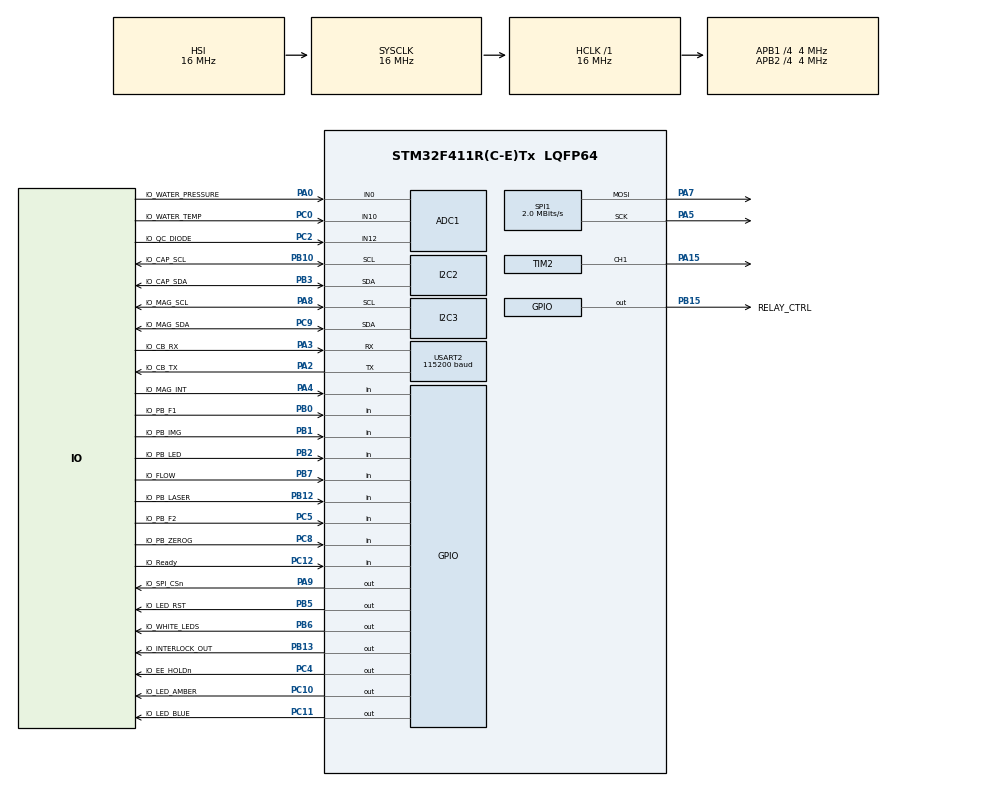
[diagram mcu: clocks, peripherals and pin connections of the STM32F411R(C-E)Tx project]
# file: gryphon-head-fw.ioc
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ADC1.Channel-0\#ChannelRegularConversion=ADC_CHANNEL_10
ADC1.ClockPrescaler=ADC_CLOCK_SYNC_PCLK_DIV6
ADC1.DMAContinuousRequests=ENABLE
ADC1.NbrOfConversionFlag=1
ADC1.Rank-0\#ChannelRegularConversion=1
ADC1.SamplingTime-0\#ChannelRegularConversion=ADC_SAMPLETIME_3CYCLES
ADC1.master=1
Dma.ADC1.0.Direction=DMA_PERIPH_TO_MEMORY
Dma.ADC1.0.FIFOMode=DMA_FIFOMODE_DISABLE
Dma.ADC1.0.Instance=DMA2_Stream0
Dma.ADC1.0.MemDataAlignment=DMA_MDATAALIGN_HALFWORD
Dma.ADC1.0.MemInc=DMA_MINC_ENABLE
Dma.ADC1.0.Mode=DMA_NORMAL
Dma.ADC1.0.PeriphDataAlignment=DMA_PDATAALIGN_HALFWORD
Dma.ADC1.0.PeriphInc=DMA_PINC_DISABLE
Dma.ADC1.0.Priority=DMA_PRIORITY_LOW
Dma.Request0=ADC1
IWDG.Prescaler=IWDG_PRESCALER_32
IWDG.Reload=1499
Mcu.Family=STM32F4
Mcu.Name=STM32F411R(C-E)Tx
Mcu.Package=LQFP64
NVIC.ADC_IRQn=true\:0\:0\:false\:false\:true\:true\:true\:true
NVIC.DMA2_Stream0_IRQn=true\:0\:0\:false\:false\:true\:false\:true\:true
NVIC.I2C2_ER_IRQn=true\:0\:0\:false\:false\:true\:true\:true\:true
NVIC.I2C2_EV_IRQn=true\:0\:0\:false\:false\:true\:true\:true\:true
NVIC.I2C3_EV_IRQn=true\:0\:0\:false\:false\:true\:true\:true\:true
NVIC.PriorityGroup=NVIC_PRIORITYGROUP_4
NVIC.TIM1_UP_TIM10_IRQn=true\:0\:0\:false\:false\:true\:true\:true\:true
NVIC.USART2_IRQn=true\:0\:0\:false\:false\:true\:true\:true\:true
PA0-WKUP.GPIO_Label=IO_WATER_PRESSURE
PA0-WKUP.Signal=ADCx_IN0
PA13.Signal=SYS_JTMS-SWDIO
PA14.Signal=SYS_JTCK-SWCLK
PA15.Signal=S_TIM2_CH1_ETR
PA2.GPIO_Label=IO_CB_TX
PA2.Mode=Asynchronous
PA2.Signal=USART2_TX
PA3.GPIO_Label=IO_CB_RX
PA3.Mode=Asynchronous
PA3.Signal=USART2_RX
PA4.GPIO_Label=IO_MAG_INT
PA4.Signal=GPIO_Input
PA5.Mode=TX_Only_Simplex_Unidirect_Master
PA5.Signal=SPI1_SCK
PA7.Mode=TX_Only_Simplex_Unidirect_Master
PA7.Signal=SPI1_MOSI
PA8.GPIO_Label=IO_MAG_SCL
PA8.GPIO_Pu=GPIO_PULLUP
PA8.Mode=I2C
PA8.Signal=I2C3_SCL
PA9.GPIO_Label=IO_SPI_CSn
PA9.GPIO_Speed=GPIO_SPEED_FREQ_VERY_HIGH
PA9.PinState=GPIO_PIN_SET
PA9.Signal=GPIO_Output
PB0.GPIO_Label=IO_PB_F1
PB0.GPIO_PuPd=GPIO_PULLUP
PB0.Signal=GPIO_Input
PB1.GPIO_Label=IO_PB_IMG
PB1.GPIO_PuPd=GPIO_PULLUP
PB1.Signal=GPIO_Input
PB10.GPIO_Label=IO_CAP_SCL
PB10.GPIO_Pu=GPIO_PULLUP
PB10.Mode=I2C
PB10.Signal=I2C2_SCL
PB12.GPIO_Label=IO_PB_LASER
PB12.GPIO_PuPd=GPIO_PULLUP
PB12.Signal=GPIO_Input
PB13.GPIO_Label=IO_INTERLOCK_OUT
PB13.Signal=GPIO_Output
PB15.GPIO_Label=RELAY_CTRL
PB15.Signal=GPIO_Output
PB2.GPIO_Label=IO_PB_LED
PB2.GPIO_PuPd=GPIO_PULLUP
PB2.Signal=GPIO_Input
PB3.GPIO_Label=IO_CAP_SDA
PB3.GPIO_Pu=GPIO_PULLUP
PB3.Mode=I2C
PB3.Signal=I2C2_SDA
PB5.GPIO_Label=IO_LED_RST
PB5.PinState=GPIO_PIN_SET
PB5.Signal=GPIO_Output
PB6.GPIO_Label=IO_WHITE_LEDS
PB6.GPIO_Speed=GPIO_SPEED_FREQ_LOW
PB6.Signal=GPIO_Output
PB7.GPIO_Label=IO_FLOW
PB7.Signal=GPIO_Input
PB8.GPIO_Label=IO_LED_SCL
PB8.GPIO_Pu=GPIO_PULLUP
PB8.Signal=I2C1_SCL
PB9.GPIO_Label=IO_LED_SDA
PB9.GPIO_Pu=GPIO_PULLUP
PB9.Signal=I2C1_SDA
PC0.GPIO_Label=IO_WATER_TEMP
PC0.Signal=ADCx_IN10
PC10.GPIO_Label=IO_LED_AMBER
PC10.Signal=GPIO_Output
PC11.GPIO_Label=IO_LED_BLUE
PC11.Signal=GPIO_Output
PC12.GPIO_Label=IO_Ready
PC12.Signal=GPIO_Input
PC2.GPIO_Label=IO_QC_DIODE
PC2.Signal=ADCx_IN12
PC4.GPIO_Label=IO_EE_HOLDn
PC4.PinState=GPIO_PIN_SET
PC4.Signal=GPIO_Output
PC5.GPIO_Label=IO_PB_F2
PC5.GPIO_PuPd=GPIO_PULLUP
PC5.Signal=GPIO_Input
PC8.GPIO_Label=IO_PB_ZEROG
PC8.Signal=GPIO_Input
PC9.GPIO_Label=IO_MAG_SDA
PC9.GPIO_Pu=GPIO_PULLUP
PC9.Mode=I2C
PC9.Signal=I2C3_SDA
PH0\ -\ OSC_IN.Mode=HSE-External-Oscillator
PH0\ -\ OSC_IN.Signal=RCC_OSC_IN
PH1\ -\ OSC_OUT.Mode=HSE-External-Oscillator
PH1\ -\ OSC_OUT.Signal=RCC_OSC_OUT
ProjectManager.HeapSize=0x200
ProjectManager.StackSize=0x400
ProjectManager.TargetToolchain=STM32CubeIDE
RCC.48MHZClocksFreq_Value=32000000
RCC.AHBFreq_Value=16000000
RCC.APB1CLKDivider=RCC_HCLK_DIV4
RCC.APB1Freq_Value=4000000
RCC.APB1TimFreq_Value=8000000
RCC.APB2CLKDivider=RCC_HCLK_DIV4
RCC.APB2Freq_Value=4000000
RCC.APB2TimFreq_Value=8000000
RCC.CortexFreq_Value=16000000
RCC.HCLKFreq_Value=16000000
RCC.HSE_VALUE=25000000
RCC.HSI_VALUE=16000000
RCC.LSE_VALUE=32768
RCC.PLLM=8
RCC.PLLN=64
RCC.SYSCLKFreq_VALUE=16000000
RCC.VCOOutputFreq_Value=128000000
SH.ADCx_IN0.0=ADC1_IN0,IN0
SH.ADCx_IN10.0=ADC1_IN10,IN10
SH.ADCx_IN12.0=ADC1_IN12,IN12
SH.S_TIM2_CH1_ETR.0=TIM2_CH1,PWM Generation1 CH1
SPI1.CLKPhase=SPI_PHASE_2EDGE
SPI1.CLKPolarity=SPI_POLARITY_HIGH
SPI1.CalculateBaudRate=2.0 MBits/s
SPI1.Direction=SPI_DIRECTION_2LINES
SPI1.Mode=SPI_MODE_MASTER
SPI1.VirtualType=VM_MASTER
TIM10.Channel=TIM_CHANNEL_1
TIM10.Prescaler=3200
TIM10.Pulse=10
TIM2.Channel-PWM\ Generation1\ CH1=TIM_CHANNEL_1
TIM2.Period=1000-1
TIM2.Prescaler=72-1
TIM2.TIM_MasterOutputTrigger=TIM_TRGO_UPDATE
USART2.BaudRate=115200
USART2.VirtualMode=VM_ASYNC
VP_IWDG_VS_IWDG.Mode=IWDG_Activate
VP_TIM10_VS_ClockSourceINT.Mode=Enable_Timer
VP_TIM10_VS_no_output1.Mode=Output Compare1 No Output
VP_TIM2_VS_ClockSourceINT.Mode=Internal
board=custom

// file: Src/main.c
/* USER CODE BEGIN Header */
/**
  ******************************************************************************
  * @file           : main.c
  * @brief          : Main program body
  ******************************************************************************
  * @attention
  *
  * <h2><center>&copy; Copyright (c) 2019 STMicroelectronics.
  * All rights reserved.</center></h2>
  *
  * This software component is licensed by ST under BSD 3-Clause license,
  * the "License"; You may not use this file except in compliance with the
  * License. You may obtain a copy of the License at:
  *                        opensource.org/licenses/BSD-3-Clause
  *
  ******************************************************************************
  */
/* USER CODE END Header */
#include "main.h"

/* USER CODE BEGIN Includes */
#include "../SensusSrc/setup.h"
/* USER CODE END Includes */

ADC_HandleTypeDef hadc1;
DMA_HandleTypeDef hdma_adc1;

I2C_HandleTypeDef hi2c2;
I2C_HandleTypeDef hi2c3;

IWDG_HandleTypeDef hiwdg;

SPI_HandleTypeDef hspi1;

TIM_HandleTypeDef htim2;
TIM_HandleTypeDef htim10;

UART_HandleTypeDef huart2;

void SystemClock_Config(void);
static void MX_GPIO_Init(void);
static void MX_DMA_Init(void);
static void MX_ADC1_Init(void);
static void MX_I2C2_Init(void);
static void MX_I2C3_Init(void);
static void MX_USART2_UART_Init(void);
static void MX_TIM10_Init(void);
static void MX_IWDG_Init(void);
static void MX_SPI1_Init(void);
static void MX_TIM2_Init(void);

int main(void)
{

  /* MCU Configuration--------------------------------------------------------*/

  /* Reset of all peripherals, Initializes the Flash interface and the Systick. */
  HAL_Init();

  /* Configure the system clock */
  SystemClock_Config();

  /* Initialize all configured peripherals */
  MX_GPIO_Init();
  MX_DMA_Init();
  MX_ADC1_Init();
  MX_I2C2_Init();
  MX_I2C3_Init();
  MX_USART2_UART_Init();
  MX_TIM10_Init();
  MX_IWDG_Init();
  MX_SPI1_Init();
  MX_TIM2_Init();
  /* USER CODE BEGIN 2 */
  run_setup();
  /* USER CODE END 2 */

  /* Infinite loop */
  /* USER CODE BEGIN WHILE */
  while (1)
  {
	  run_loop();

	  // Pet the dog. 1.5ms wdg timeout.
	  HAL_IWDG_Refresh(&hiwdg);
    /* USER CODE END WHILE */

  }
}

void SystemClock_Config(void)
{
  RCC_OscInitTypeDef RCC_OscInitStruct = {0};
  RCC_ClkInitTypeDef RCC_ClkInitStruct = {0};

  /** Configure the main internal regulator output voltage
  */
  __HAL_RCC_PWR_CLK_ENABLE();
  __HAL_PWR_VOLTAGESCALING_CONFIG(PWR_REGULATOR_VOLTAGE_SCALE1);

  /** Initializes the RCC Oscillators according to the specified parameters
  * in the RCC_OscInitTypeDef structure.
  */
  RCC_OscInitStruct.OscillatorType = RCC_OSCILLATORTYPE_HSI|RCC_OSCILLATORTYPE_LSI;
  RCC_OscInitStruct.HSIState = RCC_HSI_ON;
  RCC_OscInitStruct.HSICalibrationValue = RCC_HSICALIBRATION_DEFAULT;
  RCC_OscInitStruct.LSIState = RCC_LSI_ON;
  RCC_OscInitStruct.PLL.PLLState = RCC_PLL_NONE;
  if (HAL_RCC_OscConfig(&RCC_OscInitStruct) != HAL_OK)
  {
    Error_Handler();
  }

  /** Initializes the CPU, AHB and APB buses clocks
  */
  RCC_ClkInitStruct.ClockType = RCC_CLOCKTYPE_HCLK|RCC_CLOCKTYPE_SYSCLK
                              |RCC_CLOCKTYPE_PCLK1|RCC_CLOCKTYPE_PCLK2;
  RCC_ClkInitStruct.SYSCLKSource = RCC_SYSCLKSOURCE_HSI;
  RCC_ClkInitStruct.AHBCLKDivider = RCC_SYSCLK_DIV1;
  RCC_ClkInitStruct.APB1CLKDivider = RCC_HCLK_DIV4;
  RCC_ClkInitStruct.APB2CLKDivider = RCC_HCLK_DIV4;

  if (HAL_RCC_ClockConfig(&RCC_ClkInitStruct, FLASH_LATENCY_0) != HAL_OK)
  {
    Error_Handler();
  }
}

static void MX_ADC1_Init(void)
{

  ADC_ChannelConfTypeDef sConfig = {0};

  /** Configure the global features of the ADC (Clock, Resolution, Data Alignment and number of conversion)
  */
  hadc1.Instance = ADC1;
  hadc1.Init.ClockPrescaler = ADC_CLOCK_SYNC_PCLK_DIV6;
  hadc1.Init.Resolution = ADC_RESOLUTION_12B;
  hadc1.Init.ScanConvMode = DISABLE;
  hadc1.Init.ContinuousConvMode = DISABLE;
  hadc1.Init.DiscontinuousConvMode = DISABLE;
  hadc1.Init.ExternalTrigConvEdge = ADC_EXTERNALTRIGCONVEDGE_NONE;
  hadc1.Init.ExternalTrigConv = ADC_SOFTWARE_START;
  hadc1.Init.DataAlign = ADC_DATAALIGN_RIGHT;
  hadc1.Init.NbrOfConversion = 1;
  hadc1.Init.DMAContinuousRequests = ENABLE;
  hadc1.Init.EOCSelection = ADC_EOC_SINGLE_CONV;
  if (HAL_ADC_Init(&hadc1) != HAL_OK)
  {
    Error_Handler();
  }

  /** Configure for the selected ADC regular channel its corresponding rank in the sequencer and its sample time.
  */
  sConfig.Channel = ADC_CHANNEL_10;
  sConfig.Rank = 1;
  sConfig.SamplingTime = ADC_SAMPLETIME_3CYCLES;
  if (HAL_ADC_ConfigChannel(&hadc1, &sConfig) != HAL_OK)
  {
    Error_Handler();
  }

}

static void MX_I2C2_Init(void)
{

  hi2c2.Instance = I2C2;
  hi2c2.Init.ClockSpeed = 100000;
  hi2c2.Init.DutyCycle = I2C_DUTYCYCLE_2;
  hi2c2.Init.OwnAddress1 = 0;
  hi2c2.Init.AddressingMode = I2C_ADDRESSINGMODE_7BIT;
  hi2c2.Init.DualAddressMode = I2C_DUALADDRESS_DISABLE;
  hi2c2.Init.OwnAddress2 = 0;
  hi2c2.Init.GeneralCallMode = I2C_GENERALCALL_DISABLE;
  hi2c2.Init.NoStretchMode = I2C_NOSTRETCH_DISABLE;
  if (HAL_I2C_Init(&hi2c2) != HAL_OK)
  {
    Error_Handler();
  }

}

static void MX_I2C3_Init(void)
{

  hi2c3.Instance = I2C3;
  hi2c3.Init.ClockSpeed = 100000;
  hi2c3.Init.DutyCycle = I2C_DUTYCYCLE_2;
  hi2c3.Init.OwnAddress1 = 0;
  hi2c3.Init.AddressingMode = I2C_ADDRESSINGMODE_7BIT;
  hi2c3.Init.DualAddressMode = I2C_DUALADDRESS_DISABLE;
  hi2c3.Init.OwnAddress2 = 0;
  hi2c3.Init.GeneralCallMode = I2C_GENERALCALL_DISABLE;
  hi2c3.Init.NoStretchMode = I2C_NOSTRETCH_DISABLE;
  if (HAL_I2C_Init(&hi2c3) != HAL_OK)
  {
    Error_Handler();
  }

}

static void MX_IWDG_Init(void)
{

  hiwdg.Instance = IWDG;
  hiwdg.Init.Prescaler = IWDG_PRESCALER_32;
  hiwdg.Init.Reload = 1499;
  if (HAL_IWDG_Init(&hiwdg) != HAL_OK)
  {
    Error_Handler();
  }

}

static void MX_SPI1_Init(void)
{

  /* SPI1 parameter configuration*/
  hspi1.Instance = SPI1;
  hspi1.Init.Mode = SPI_MODE_MASTER;
  hspi1.Init.Direction = SPI_DIRECTION_2LINES;
  hspi1.Init.DataSize = SPI_DATASIZE_8BIT;
  hspi1.Init.CLKPolarity = SPI_POLARITY_HIGH;
  hspi1.Init.CLKPhase = SPI_PHASE_2EDGE;
  hspi1.Init.NSS = SPI_NSS_SOFT;
  hspi1.Init.BaudRatePrescaler = SPI_BAUDRATEPRESCALER_2;
  hspi1.Init.FirstBit = SPI_FIRSTBIT_MSB;
  hspi1.Init.TIMode = SPI_TIMODE_DISABLE;
  hspi1.Init.CRCCalculation = SPI_CRCCALCULATION_DISABLE;
  hspi1.Init.CRCPolynomial = 10;
  if (HAL_SPI_Init(&hspi1) != HAL_OK)
  {
    Error_Handler();
  }

}

static void MX_TIM2_Init(void)
{

  TIM_ClockConfigTypeDef sClockSourceConfig = {0};
  TIM_MasterConfigTypeDef sMasterConfig = {0};
  TIM_OC_InitTypeDef sConfigOC = {0};

  htim2.Instance = TIM2;
  htim2.Init.Prescaler = 72-1;
  htim2.Init.CounterMode = TIM_COUNTERMODE_UP;
  htim2.Init.Period = 1000-1;
  htim2.Init.ClockDivision = TIM_CLOCKDIVISION_DIV1;
  htim2.Init.AutoReloadPreload = TIM_AUTORELOAD_PRELOAD_DISABLE;
  if (HAL_TIM_Base_Init(&htim2) != HAL_OK)
  {
    Error_Handler();
  }
  sClockSourceConfig.ClockSource = TIM_CLOCKSOURCE_INTERNAL;
  if (HAL_TIM_ConfigClockSource(&htim2, &sClockSourceConfig) != HAL_OK)
  {
    Error_Handler();
  }
  if (HAL_TIM_PWM_Init(&htim2) != HAL_OK)
  {
    Error_Handler();
  }
  sMasterConfig.MasterOutputTrigger = TIM_TRGO_UPDATE;
  sMasterConfig.MasterSlaveMode = TIM_MASTERSLAVEMODE_DISABLE;
  if (HAL_TIMEx_MasterConfigSynchronization(&htim2, &sMasterConfig) != HAL_OK)
  {
    Error_Handler();
  }
  sConfigOC.OCMode = TIM_OCMODE_PWM1;
  sConfigOC.Pulse = 0;
  sConfigOC.OCPolarity = TIM_OCPOLARITY_HIGH;
  sConfigOC.OCFastMode = TIM_OCFAST_DISABLE;
  if (HAL_TIM_PWM_ConfigChannel(&htim2, &sConfigOC, TIM_CHANNEL_1) != HAL_OK)
  {
    Error_Handler();
  }
  HAL_TIM_MspPostInit(&htim2);

}

static void MX_TIM10_Init(void)
{

  TIM_OC_InitTypeDef sConfigOC = {0};

  htim10.Instance = TIM10;
  htim10.Init.Prescaler = 3200;
  htim10.Init.CounterMode = TIM_COUNTERMODE_UP;
  htim10.Init.Period = 65535;
  htim10.Init.ClockDivision = TIM_CLOCKDIVISION_DIV1;
  htim10.Init.AutoReloadPreload = TIM_AUTORELOAD_PRELOAD_DISABLE;
  if (HAL_TIM_Base_Init(&htim10) != HAL_OK)
  {
    Error_Handler();
  }
  if (HAL_TIM_OC_Init(&htim10) != HAL_OK)
  {
    Error_Handler();
  }
  sConfigOC.OCMode = TIM_OCMODE_TIMING;
  sConfigOC.Pulse = 10;
  sConfigOC.OCPolarity = TIM_OCPOLARITY_HIGH;
  sConfigOC.OCFastMode = TIM_OCFAST_DISABLE;
  if (HAL_TIM_OC_ConfigChannel(&htim10, &sConfigOC, TIM_CHANNEL_1) != HAL_OK)
  {
    Error_Handler();
  }

}

static void MX_USART2_UART_Init(void)
{

  huart2.Instance = USART2;
  huart2.Init.BaudRate = 115200;
  huart2.Init.WordLength = UART_WORDLENGTH_8B;
  huart2.Init.StopBits = UART_STOPBITS_1;
  huart2.Init.Parity = UART_PARITY_NONE;
  huart2.Init.Mode = UART_MODE_TX_RX;
  huart2.Init.HwFlowCtl = UART_HWCONTROL_NONE;
  huart2.Init.OverSampling = UART_OVERSAMPLING_16;
  if (HAL_UART_Init(&huart2) != HAL_OK)
  {
    Error_Handler();
  }

}

static void MX_DMA_Init(void)
{

  /* DMA controller clock enable */
  __HAL_RCC_DMA2_CLK_ENABLE();

  /* DMA interrupt init */
  /* DMA2_Stream0_IRQn interrupt configuration */
  HAL_NVIC_SetPriority(DMA2_Stream0_IRQn, 0, 0);
  HAL_NVIC_EnableIRQ(DMA2_Stream0_IRQn);

}

static void MX_GPIO_Init(void)
{
  GPIO_InitTypeDef GPIO_InitStruct = {0};

  /* GPIO Ports Clock Enable */
  __HAL_RCC_GPIOH_CLK_ENABLE();
  __HAL_RCC_GPIOC_CLK_ENABLE();
  __HAL_RCC_GPIOA_CLK_ENABLE();
  __HAL_RCC_GPIOB_CLK_ENABLE();

  /*Configure GPIO pin Output Level */
  HAL_GPIO_WritePin(IO_EE_HOLDn_GPIO_Port, IO_EE_HOLDn_Pin, GPIO_PIN_SET);

  /*Configure GPIO pin Output Level */
  HAL_GPIO_WritePin(GPIOB, IO_INTERLOCK_OUT_Pin|RELAY_CTRL_Pin|IO_WHITE_LEDS_Pin, GPIO_PIN_RESET);

  /*Configure GPIO pin Output Level */
  HAL_GPIO_WritePin(IO_SPI_CSn_GPIO_Port, IO_SPI_CSn_Pin, GPIO_PIN_SET);

  /*Configure GPIO pin Output Level */
  HAL_GPIO_WritePin(GPIOC, IO_LED_AMBER_Pin|IO_LED_BLUE_Pin, GPIO_PIN_RESET);

  /*Configure GPIO pin Output Level */
  HAL_GPIO_WritePin(IO_LED_RST_GPIO_Port, IO_LED_RST_Pin, GPIO_PIN_SET);

  /*Configure GPIO pin : IO_MAG_INT_Pin */
  GPIO_InitStruct.Pin = IO_MAG_INT_Pin;
  GPIO_InitStruct.Mode = GPIO_MODE_INPUT;
  GPIO_InitStruct.Pull = GPIO_NOPULL;
  HAL_GPIO_Init(IO_MAG_INT_GPIO_Port, &GPIO_InitStruct);

  /*Configure GPIO pins : IO_EE_HOLDn_Pin IO_LED_AMBER_Pin IO_LED_BLUE_Pin */
  GPIO_InitStruct.Pin = IO_EE_HOLDn_Pin|IO_LED_AMBER_Pin|IO_LED_BLUE_Pin;
  GPIO_InitStruct.Mode = GPIO_MODE_OUTPUT_PP;
  GPIO_InitStruct.Pull = GPIO_NOPULL;
  GPIO_InitStruct.Speed = GPIO_SPEED_FREQ_LOW;
  HAL_GPIO_Init(GPIOC, &GPIO_InitStruct);

  /*Configure GPIO pin : IO_PB_F2_Pin */
  GPIO_InitStruct.Pin = IO_PB_F2_Pin;
  GPIO_InitStruct.Mode = GPIO_MODE_INPUT;
  GPIO_InitStruct.Pull = GPIO_PULLUP;
  HAL_GPIO_Init(IO_PB_F2_GPIO_Port, &GPIO_InitStruct);

  /*Configure GPIO pins : IO_PB_F1_Pin IO_PB_IMG_Pin IO_PB_LED_Pin IO_PB_LASER_Pin */
  GPIO_InitStruct.Pin = IO_PB_F1_Pin|IO_PB_IMG_Pin|IO_PB_LED_Pin|IO_PB_LASER_Pin;
  GPIO_InitStruct.Mode = GPIO_MODE_INPUT;
  GPIO_InitStruct.Pull = GPIO_PULLUP;
  HAL_GPIO_Init(GPIOB, &GPIO_InitStruct);

  /*Configure GPIO pins : IO_INTERLOCK_OUT_Pin RELAY_CTRL_Pin IO_LED_RST_Pin IO_WHITE_LEDS_Pin */
  GPIO_InitStruct.Pin = IO_INTERLOCK_OUT_Pin|RELAY_CTRL_Pin|IO_LED_RST_Pin|IO_WHITE_LEDS_Pin;
  GPIO_InitStruct.Mode = GPIO_MODE_OUTPUT_PP;
  GPIO_InitStruct.Pull = GPIO_NOPULL;
  GPIO_InitStruct.Speed = GPIO_SPEED_FREQ_LOW;
  HAL_GPIO_Init(GPIOB, &GPIO_InitStruct);

  /*Configure GPIO pins : IO_PB_ZEROG_Pin IO_Ready_Pin */
  GPIO_InitStruct.Pin = IO_PB_ZEROG_Pin|IO_Ready_Pin;
  GPIO_InitStruct.Mode = GPIO_MODE_INPUT;
  GPIO_InitStruct.Pull = GPIO_NOPULL;
  HAL_GPIO_Init(GPIOC, &GPIO_InitStruct);

  /*Configure GPIO pin : IO_SPI_CSn_Pin */
  GPIO_InitStruct.Pin = IO_SPI_CSn_Pin;
  GPIO_InitStruct.Mode = GPIO_MODE_OUTPUT_PP;
  GPIO_InitStruct.Pull = GPIO_NOPULL;
  GPIO_InitStruct.Speed = GPIO_SPEED_FREQ_VERY_HIGH;
  HAL_GPIO_Init(IO_SPI_CSn_GPIO_Port, &GPIO_InitStruct);

  /*Configure GPIO pin : IO_FLOW_Pin */
  GPIO_InitStruct.Pin = IO_FLOW_Pin;
  GPIO_InitStruct.Mode = GPIO_MODE_INPUT;
  GPIO_InitStruct.Pull = GPIO_NOPULL;
  HAL_GPIO_Init(IO_FLOW_GPIO_Port, &GPIO_InitStruct);

  /*Configure GPIO pins : IO_LED_SCL_Pin IO_LED_SDA_Pin */
  GPIO_InitStruct.Pin = IO_LED_SCL_Pin|IO_LED_SDA_Pin;
  GPIO_InitStruct.Mode = GPIO_MODE_AF_OD;
  GPIO_InitStruct.Pull = GPIO_PULLUP;
  GPIO_InitStruct.Speed = GPIO_SPEED_FREQ_VERY_HIGH;
  GPIO_InitStruct.Alternate = GPIO_AF4_I2C1;
  HAL_GPIO_Init(GPIOB, &GPIO_InitStruct);

}

void Error_Handler(void)
{
}
